VERSION ""

NS_ :

BS_:

BU_: ECU EPS ABS Gateway

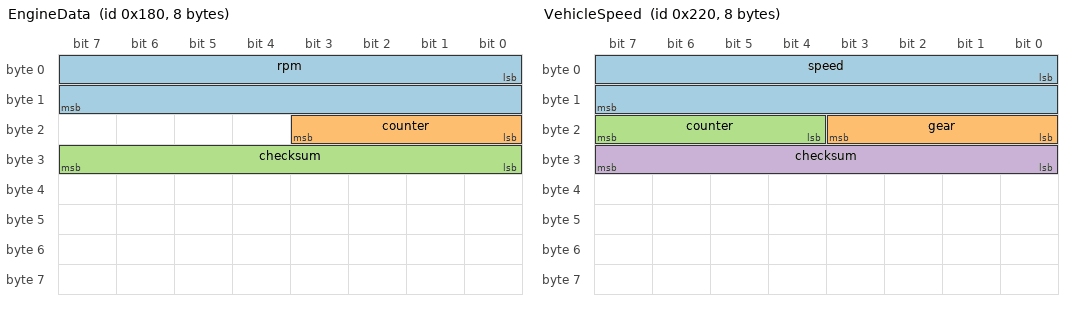
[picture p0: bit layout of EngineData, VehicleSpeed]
BO_ 384 EngineData: 8 ECU
 SG_ rpm : 0|16@1+ (0.25,0) [0|16000] "rpm" Gateway
 SG_ counter : 16|4@1+ (1,0) [0|15] "" Gateway
 SG_ checksum : 24|8@1+ (1,0) [0|255] "" Gateway

BO_ 544 VehicleSpeed: 8 ECU
 SG_ speed : 0|16@1+ (0.01,0) [0|655.35] "km/h" Gateway
 SG_ gear : 16|4@1+ (1,0) [0|5] "" Gateway
 SG_ counter : 20|4@1+ (1,0) [0|15] "" Gateway
 SG_ checksum : 24|8@1+ (1,0) [0|255] "" Gateway

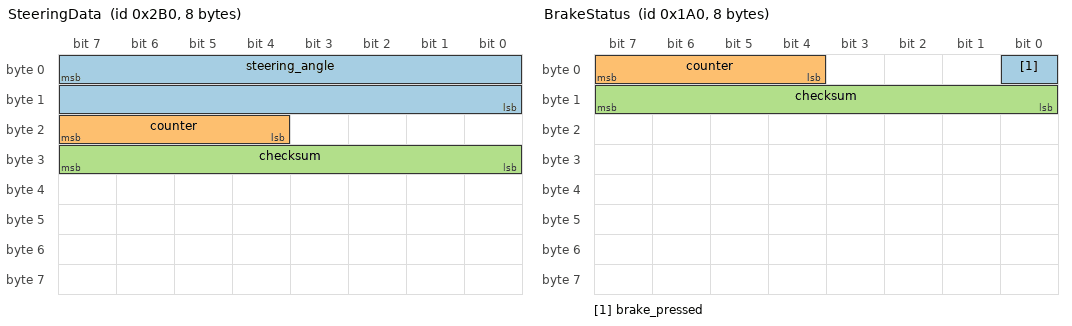
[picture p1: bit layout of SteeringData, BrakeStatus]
BO_ 688 SteeringData: 8 EPS
 SG_ steering_angle : 7|16@0- (0.1,0) [-780|780] "deg" Gateway
 SG_ counter : 23|4@0+ (1,0) [0|15] "" Gateway
 SG_ checksum : 31|8@0+ (1,0) [0|255] "" Gateway

BO_ 416 BrakeStatus: 8 ABS
 SG_ brake_pressed : 0|1@1+ (1,0) [0|1] "" Gateway
 SG_ counter : 4|4@1+ (1,0) [0|15] "" Gateway
 SG_ checksum : 8|8@1+ (1,0) [0|255] "" Gateway

CM_ BO_ 384 "Engine RPM and status, transmitted every 20 ms by the ECU.";
CM_ BO_ 544 "Vehicle speed and gear selector state, transmitted every 20 ms by the ECU.";
CM_ BO_ 688 "Steering angle, transmitted every 10 ms by the EPS module.";
CM_ BO_ 416 "Brake pedal status, transmitted every 20 ms by the ABS module.";
CM_ SG_ 384 checksum "XOR of the other 7 bytes in the frame.";
CM_ SG_ 544 checksum "XOR of the other 7 bytes in the frame.";
CM_ SG_ 688 checksum "XOR of the other 7 bytes in the frame.";
CM_ SG_ 416 checksum "XOR of the other 7 bytes in the frame.";

VAL_ 544 gear 0 "P" 1 "R" 2 "N" 3 "D1" 4 "D2" 5 "D3" ;
VAL_ 416 brake_pressed 0 "OFF" 1 "ON" ;
